AUTOSAR XML (schema 4-0-3)
standard types defined: Boolean, UInt16
package /AUTOSAR_Platform/DataConstrs
  range DC_Boolean: raw 0..1
  range DC_UInt16: raw 0..65535
package /PATAC/MSM/ComponentTypes
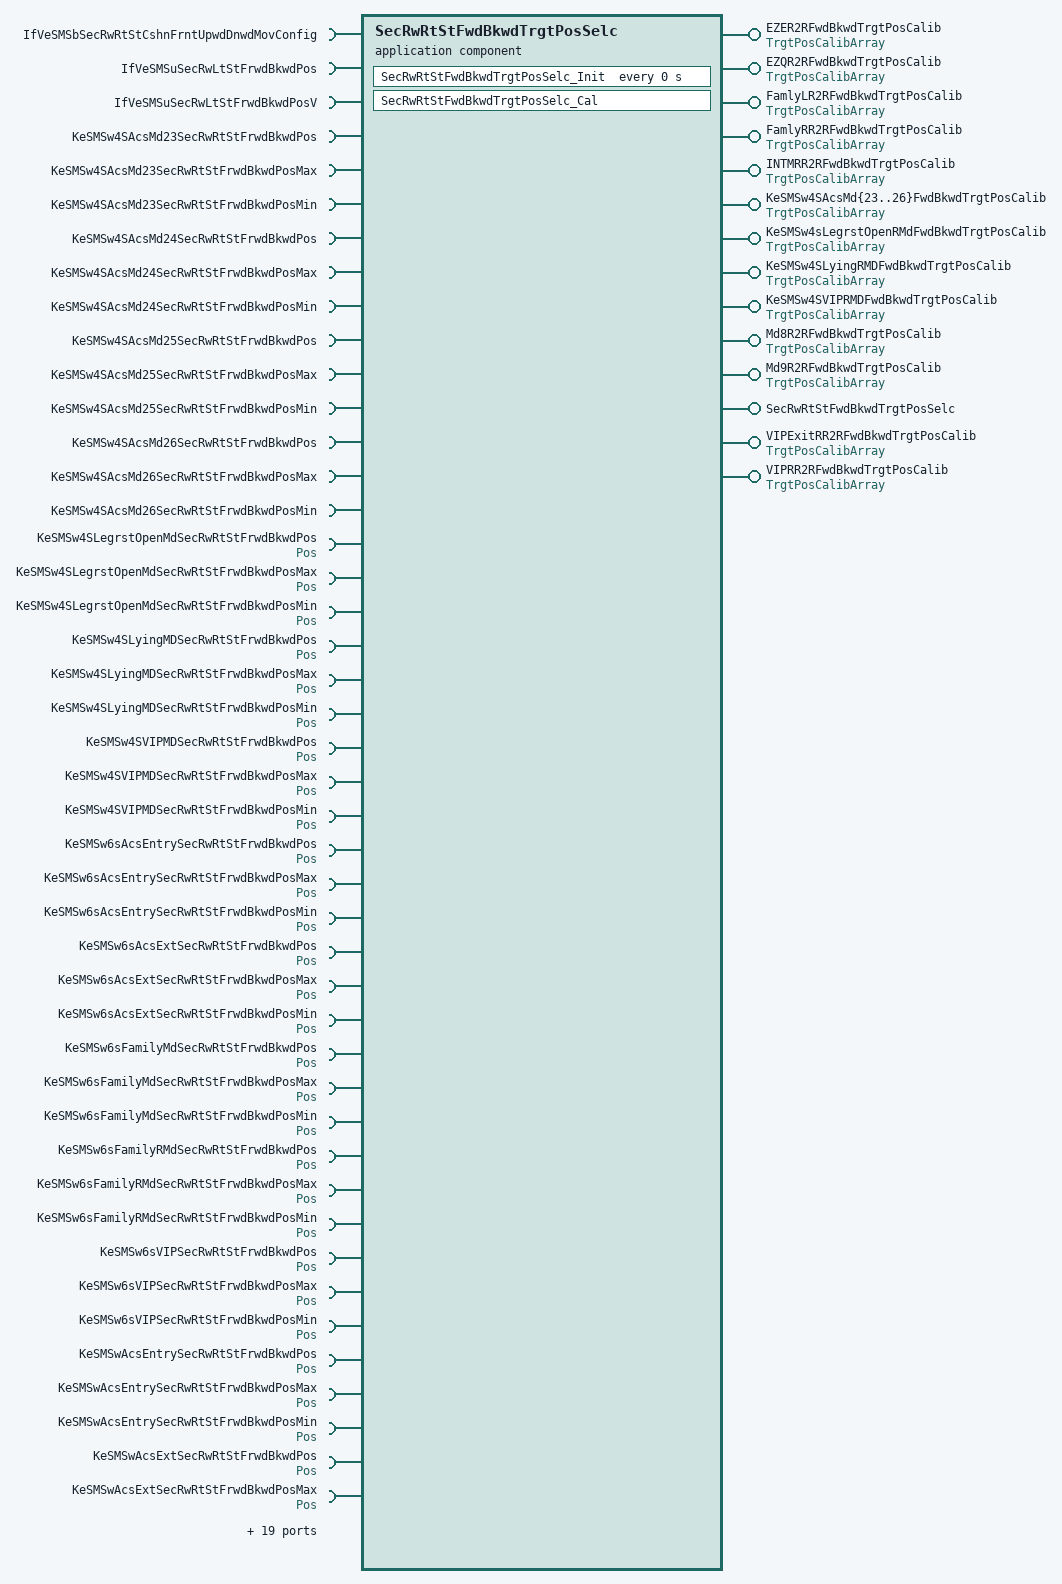
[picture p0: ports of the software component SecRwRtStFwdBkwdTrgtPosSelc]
  application sw component type SecRwRtStFwdBkwdTrgtPosSelc
    17 x provide port:
      EZER2RFwdBkwdTrgtPosCalib: nonqueued-sender-com-spec{data-element=TrgtPosArray, init-value=[4095, 4095, 4095]}, provided-interface=TrgtPosCalibArray
      EZQR2RFwdBkwdTrgtPosCalib: nonqueued-sender-com-spec{data-element=TrgtPosArray, init-value=[4095, 4095, 4095]}, provided-interface=TrgtPosCalibArray
      FamlyLR2RFwdBkwdTrgtPosCalib: nonqueued-sender-com-spec{data-element=TrgtPosArray, init-value=[4095, 4095, 4095]}, provided-interface=TrgtPosCalibArray
      FamlyRR2RFwdBkwdTrgtPosCalib: nonqueued-sender-com-spec{data-element=TrgtPosArray, init-value=[4095, 4095, 4095]}, provided-interface=TrgtPosCalibArray
      INTMRR2RFwdBkwdTrgtPosCalib: nonqueued-sender-com-spec{data-element=TrgtPosArray, init-value=[4095, 4095, 4095]}, provided-interface=TrgtPosCalibArray
      KeSMSw4SAcsMd{23..26}FwdBkwdTrgtPosCalib: nonqueued-sender-com-spec{data-element=TrgtPosArray, init-value=[4095, 4095, 4095]}, provided-interface=TrgtPosCalibArray
      KeSMSw4sLegrstOpenRMdFwdBkwdTrgtPosCalib: nonqueued-sender-com-spec{data-element=TrgtPosArray, init-value=[4095, 4095, 4095]}, provided-interface=TrgtPosCalibArray
      KeSMSw4SLyingRMDFwdBkwdTrgtPosCalib: nonqueued-sender-com-spec{data-element=TrgtPosArray, init-value=[4095, 4095, 4095]}, provided-interface=TrgtPosCalibArray
      KeSMSw4SVIPRMDFwdBkwdTrgtPosCalib: nonqueued-sender-com-spec{data-element=TrgtPosArray, init-value=[4095, 4095, 4095]}, provided-interface=TrgtPosCalibArray
      Md8R2RFwdBkwdTrgtPosCalib: nonqueued-sender-com-spec{data-element=TrgtPosArray, init-value=[4095, 4095, 4095]}, provided-interface=TrgtPosCalibArray
      Md9R2RFwdBkwdTrgtPosCalib: nonqueued-sender-com-spec{data-element=TrgtPosArray, init-value=[4095, 4095, 4095]}, provided-interface=TrgtPosCalibArray
      SecRwRtStFwdBkwdTrgtPosSelc: server-com-spec{operation=Cal, queue-length=1}, provided-interface=SecRwRtStFwdBkwdTrgtPosSelc
      VIPExitRR2RFwdBkwdTrgtPosCalib: nonqueued-sender-com-spec{data-element=TrgtPosArray, init-value=[4095, 4095, 4095]}, provided-interface=TrgtPosCalibArray
      VIPRR2RFwdBkwdTrgtPosCalib: nonqueued-sender-com-spec{data-element=TrgtPosArray, init-value=[4095, 4095, 4095]}, provided-interface=TrgtPosCalibArray
    63 x require port:
      IfVeSMSbSecRwRtStCshnFrntUpwdDnwdMovConfig: nonqueued-receiver-com-spec{data-element=IfVeSMSbSecRwRtStCshnFrntUpwdDnwdMovConfig/Val, filter=data-filter-type=ALWAYS, init-value=0}, required-interface=IfVeSMSbSecRwRtStCshnFrntUpwdDnwdMovConfig
      IfVeSMSuSecRwLtStFrwdBkwdPos: nonqueued-receiver-com-spec{data-element=IfVeSMSuSecRwLtStFrwdBkwdPos/Val, filter=data-filter-type=ALWAYS, init-value=0}, required-interface=IfVeSMSuSecRwLtStFrwdBkwdPos
      IfVeSMSuSecRwLtStFrwdBkwdPosV: nonqueued-receiver-com-spec{data-element=IfVeSMSuSecRwLtStFrwdBkwdPosV/Val, filter=data-filter-type=ALWAYS, init-value=0}, required-interface=IfVeSMSuSecRwLtStFrwdBkwdPosV
      KeSMSw4SAcsMd23SecRwRtStFrwdBkwdPos: parameter-require-com-spec{init-value=0, parameter=KeSMSw4SAcsMd23SecRwRtStFrwdBkwdPos/Val}, required-interface=KeSMSw4SAcsMd23SecRwRtStFrwdBkwdPos
      KeSMSw4SAcsMd23SecRwRtStFrwdBkwdPosMax: parameter-require-com-spec{init-value=0, parameter=KeSMSw4SAcsMd23SecRwRtStFrwdBkwdPosMax/Val}, required-interface=KeSMSw4SAcsMd23SecRwRtStFrwdBkwdPosMax
      KeSMSw4SAcsMd23SecRwRtStFrwdBkwdPosMin: parameter-require-com-spec{init-value=0, parameter=KeSMSw4SAcsMd23SecRwRtStFrwdBkwdPosMin/Val}, required-interface=KeSMSw4SAcsMd23SecRwRtStFrwdBkwdPosMin
      KeSMSw4SAcsMd24SecRwRtStFrwdBkwdPos: parameter-require-com-spec{init-value=0, parameter=KeSMSw4SAcsMd24SecRwRtStFrwdBkwdPos/Val}, required-interface=KeSMSw4SAcsMd24SecRwRtStFrwdBkwdPos
      KeSMSw4SAcsMd24SecRwRtStFrwdBkwdPosMax: parameter-require-com-spec{init-value=0, parameter=KeSMSw4SAcsMd24SecRwRtStFrwdBkwdPosMax/Val}, required-interface=KeSMSw4SAcsMd24SecRwRtStFrwdBkwdPosMax
      KeSMSw4SAcsMd24SecRwRtStFrwdBkwdPosMin: parameter-require-com-spec{init-value=0, parameter=KeSMSw4SAcsMd24SecRwRtStFrwdBkwdPosMin/Val}, required-interface=KeSMSw4SAcsMd24SecRwRtStFrwdBkwdPosMin
      KeSMSw4SAcsMd25SecRwRtStFrwdBkwdPos: parameter-require-com-spec{init-value=0, parameter=KeSMSw4SAcsMd25SecRwRtStFrwdBkwdPos/Val}, required-interface=KeSMSw4SAcsMd25SecRwRtStFrwdBkwdPos
      KeSMSw4SAcsMd25SecRwRtStFrwdBkwdPosMax: parameter-require-com-spec{init-value=0, parameter=KeSMSw4SAcsMd25SecRwRtStFrwdBkwdPosMax/Val}, required-interface=KeSMSw4SAcsMd25SecRwRtStFrwdBkwdPosMax
      KeSMSw4SAcsMd25SecRwRtStFrwdBkwdPosMin: parameter-require-com-spec{init-value=0, parameter=KeSMSw4SAcsMd25SecRwRtStFrwdBkwdPosMin/Val}, required-interface=KeSMSw4SAcsMd25SecRwRtStFrwdBkwdPosMin
      KeSMSw4SAcsMd26SecRwRtStFrwdBkwdPos: parameter-require-com-spec{init-value=0, parameter=KeSMSw4SAcsMd26SecRwRtStFrwdBkwdPos/Val}, required-interface=KeSMSw4SAcsMd26SecRwRtStFrwdBkwdPos
      KeSMSw4SAcsMd26SecRwRtStFrwdBkwdPosMax: parameter-require-com-spec{init-value=0, parameter=KeSMSw4SAcsMd26SecRwRtStFrwdBkwdPosMax/Val}, required-interface=KeSMSw4SAcsMd26SecRwRtStFrwdBkwdPosMax
      KeSMSw4SAcsMd26SecRwRtStFrwdBkwdPosMin: parameter-require-com-spec{init-value=0, parameter=KeSMSw4SAcsMd26SecRwRtStFrwdBkwdPosMin/Val}, required-interface=KeSMSw4SAcsMd26SecRwRtStFrwdBkwdPosMin
      KeSMSw4SLegrstOpenMdSecRwRtStFrwdBkwdPos: parameter-require-com-spec{init-value=2920, parameter=Pos/Val}, required-interface=Pos
      KeSMSw4SLegrstOpenMdSecRwRtStFrwdBkwdPosMax: parameter-require-com-spec{init-value=2920, parameter=Pos/Val}, required-interface=Pos
      KeSMSw4SLegrstOpenMdSecRwRtStFrwdBkwdPosMin: parameter-require-com-spec{init-value=2920, parameter=Pos/Val}, required-interface=Pos
      KeSMSw4SLyingMDSecRwRtStFrwdBkwdPos: parameter-require-com-spec{init-value=2920, parameter=Pos/Val}, required-interface=Pos
      KeSMSw4SLyingMDSecRwRtStFrwdBkwdPosMax: parameter-require-com-spec{init-value=2920, parameter=Pos/Val}, required-interface=Pos
      KeSMSw4SLyingMDSecRwRtStFrwdBkwdPosMin: parameter-require-com-spec{init-value=2920, parameter=Pos/Val}, required-interface=Pos
      KeSMSw4SVIPMDSecRwRtStFrwdBkwdPos: parameter-require-com-spec{init-value=2920, parameter=Pos/Val}, required-interface=Pos
      KeSMSw4SVIPMDSecRwRtStFrwdBkwdPosMax: parameter-require-com-spec{init-value=2920, parameter=Pos/Val}, required-interface=Pos
      KeSMSw4SVIPMDSecRwRtStFrwdBkwdPosMin: parameter-require-com-spec{init-value=2920, parameter=Pos/Val}, required-interface=Pos
      KeSMSw6sAcsEntrySecRwRtStFrwdBkwdPos: parameter-require-com-spec{init-value=727, parameter=Pos/Val}, required-interface=Pos
      KeSMSw6sAcsEntrySecRwRtStFrwdBkwdPosMax: parameter-require-com-spec{init-value=727, parameter=Pos/Val}, required-interface=Pos
      KeSMSw6sAcsEntrySecRwRtStFrwdBkwdPosMin: parameter-require-com-spec{init-value=727, parameter=Pos/Val}, required-interface=Pos
      KeSMSw6sAcsExtSecRwRtStFrwdBkwdPos: parameter-require-com-spec{init-value=727, parameter=Pos/Val}, required-interface=Pos
      KeSMSw6sAcsExtSecRwRtStFrwdBkwdPosMax: parameter-require-com-spec{init-value=727, parameter=Pos/Val}, required-interface=Pos
      KeSMSw6sAcsExtSecRwRtStFrwdBkwdPosMin: parameter-require-com-spec{init-value=727, parameter=Pos/Val}, required-interface=Pos
      KeSMSw6sFamilyMdSecRwRtStFrwdBkwdPos: parameter-require-com-spec{init-value=0, parameter=Pos/Val}, required-interface=Pos
      KeSMSw6sFamilyMdSecRwRtStFrwdBkwdPosMax: parameter-require-com-spec{init-value=0, parameter=Pos/Val}, required-interface=Pos
      KeSMSw6sFamilyMdSecRwRtStFrwdBkwdPosMin: parameter-require-com-spec{init-value=0, parameter=Pos/Val}, required-interface=Pos
      KeSMSw6sFamilyRMdSecRwRtStFrwdBkwdPos: parameter-require-com-spec{init-value=0, parameter=Pos/Val}, required-interface=Pos
      KeSMSw6sFamilyRMdSecRwRtStFrwdBkwdPosMax: parameter-require-com-spec{init-value=0, parameter=Pos/Val}, required-interface=Pos
      KeSMSw6sFamilyRMdSecRwRtStFrwdBkwdPosMin: parameter-require-com-spec{init-value=0, parameter=Pos/Val}, required-interface=Pos
      KeSMSw6sVIPSecRwRtStFrwdBkwdPos: parameter-require-com-spec{init-value=2920, parameter=Pos/Val}, required-interface=Pos
      KeSMSw6sVIPSecRwRtStFrwdBkwdPosMax: parameter-require-com-spec{init-value=2920, parameter=Pos/Val}, required-interface=Pos
      KeSMSw6sVIPSecRwRtStFrwdBkwdPosMin: parameter-require-com-spec{init-value=2920, parameter=Pos/Val}, required-interface=Pos
      KeSMSwAcsEntrySecRwRtStFrwdBkwdPos: parameter-require-com-spec{init-value=727, parameter=Pos/Val}, required-interface=Pos
      KeSMSwAcsEntrySecRwRtStFrwdBkwdPosMax: parameter-require-com-spec{init-value=727, parameter=Pos/Val}, required-interface=Pos
      KeSMSwAcsEntrySecRwRtStFrwdBkwdPosMin: parameter-require-com-spec{init-value=727, parameter=Pos/Val}, required-interface=Pos
      KeSMSwAcsExtSecRwRtStFrwdBkwdPos: parameter-require-com-spec{init-value=727, parameter=Pos/Val}, required-interface=Pos
      KeSMSwAcsExtSecRwRtStFrwdBkwdPosMax: parameter-require-com-spec{init-value=727, parameter=Pos/Val}, required-interface=Pos
      KeSMSwAcsExtSecRwRtStFrwdBkwdPosMin: parameter-require-com-spec{init-value=727, parameter=Pos/Val}, required-interface=Pos
      KeSMSwAcsMd8SecRwRtStFrwdBkwdPos: parameter-require-com-spec{init-value=0, parameter=Pos/Val}, required-interface=Pos
      KeSMSwAcsMd8SecRwRtStFrwdBkwdPosMax: parameter-require-com-spec{init-value=0, parameter=Pos/Val}, required-interface=Pos
      KeSMSwAcsMd8SecRwRtStFrwdBkwdPosMin: parameter-require-com-spec{init-value=0, parameter=Pos/Val}, required-interface=Pos
      KeSMSwAcsMd9SecRwRtStFrwdBkwdPos: parameter-require-com-spec{init-value=0, parameter=Pos/Val}, required-interface=Pos
      KeSMSwAcsMd9SecRwRtStFrwdBkwdPosMax: parameter-require-com-spec{init-value=0, parameter=Pos/Val}, required-interface=Pos
      KeSMSwAcsMd9SecRwRtStFrwdBkwdPosMin: parameter-require-com-spec{init-value=0, parameter=Pos/Val}, required-interface=Pos
      KeSMSwFamilyMdSecRwRtStFrwdBkwdPos: parameter-require-com-spec{init-value=0, parameter=Pos/Val}, required-interface=Pos
      KeSMSwFamilyMdSecRwRtStFrwdBkwdPosMax: parameter-require-com-spec{init-value=0, parameter=Pos/Val}, required-interface=Pos
      KeSMSwFamilyMdSecRwRtStFrwdBkwdPosMin: parameter-require-com-spec{init-value=0, parameter=Pos/Val}, required-interface=Pos
      KeSMSwFamilyRMdSecRwRtStFrwdBkwdPos: parameter-require-com-spec{init-value=0, parameter=Pos/Val}, required-interface=Pos
      KeSMSwFamilyRMdSecRwRtStFrwdBkwdPosMax: parameter-require-com-spec{init-value=0, parameter=Pos/Val}, required-interface=Pos
      KeSMSwFamilyRMdSecRwRtStFrwdBkwdPosMin: parameter-require-com-spec{init-value=0, parameter=Pos/Val}, required-interface=Pos
      KeSMSwVIPSecRwRtStFrwdBkwdPos: parameter-require-com-spec{init-value=2920, parameter=Pos/Val}, required-interface=Pos
      KeSMSwVIPSecRwRtStFrwdBkwdPosMax: parameter-require-com-spec{init-value=2920, parameter=Pos/Val}, required-interface=Pos
      KeSMSwVIPSecRwRtStFrwdBkwdPosMin: parameter-require-com-spec{init-value=2920, parameter=Pos/Val}, required-interface=Pos
      StNumFlg: required-interface=StNumFlg
        required-com-specs:
          data-element=Is4s, filter=data-filter-type=ALWAYS, init-value=0
          data-element=Is6s, filter=data-filter-type=ALWAYS, init-value=0
          data-element=Is6s7s, filter=data-filter-type=ALWAYS, init-value=0
          data-element=Is7s, filter=data-filter-type=ALWAYS, init-value=0
      VIPR557TrgtPos: required-com-specs=[VIPR557TrgtPos/Get, VIPR557TrgtPos/Set], required-interface=VIPR557TrgtPos
      VIPRExit557TrgtPos: required-com-specs=[VIPRExit557TrgtPos/Get, VIPRExit557TrgtPos/Set], required-interface=VIPRExit557TrgtPos
    behavior SecRwRtStFwdBkwdTrgtPosSelc_InternalBehavior
      operation invoked event OIT_SecRwRtStFwdBkwdTrgtPosSelc_Cal_SecRwRtStFwdBkwdTrgtPosSelc_Cal: start-on-event=SecRwRtStFwdBkwdTrgtPosSelc_Cal, operation=SecRwRtStFwdBkwdTrgtPosSelc.Cal
      timing event SecRwRtStFwdBkwdTrgtPosSelc_InitEvent: start-on-event=SecRwRtStFwdBkwdTrgtPosSelc_Init, period=0
      runnable SecRwRtStFwdBkwdTrgtPosSelc_Cal
        data-receive-point-by-arguments:
          7 x access:
            REC_IfVeSMSbSecRwRtStCshnFrntUpwdDnwdMovConfig_Val: accessed-variable=IfVeSMSbSecRwRtStCshnFrntUpwdDnwdMovConfig.Val
            REC_IfVeSMSuSecRwLtStFrwdBkwdPos_Val: accessed-variable=IfVeSMSuSecRwLtStFrwdBkwdPos.Val
            REC_IfVeSMSuSecRwLtStFrwdBkwdPosV_Val: accessed-variable=IfVeSMSuSecRwLtStFrwdBkwdPosV.Val
            REC_StNumFlg_Is4s: accessed-variable=StNumFlg.Is4s
            REC_StNumFlg_Is6s: accessed-variable=StNumFlg.Is6s
            REC_StNumFlg_Is6s7s: accessed-variable=StNumFlg.Is6s7s
            REC_StNumFlg_Is7s: accessed-variable=StNumFlg.Is7s
        data-send-points:
          16 x access:
            SEND_EZER2RFwdBkwdTrgtPosCalib_TrgtPosArray: accessed-variable=EZER2RFwdBkwdTrgtPosCalib.TrgtPosArray
            SEND_EZQR2RFwdBkwdTrgtPosCalib_TrgtPosArray: accessed-variable=EZQR2RFwdBkwdTrgtPosCalib.TrgtPosArray
            SEND_FamlyLR2RFwdBkwdTrgtPosCalib_TrgtPosArray: accessed-variable=FamlyLR2RFwdBkwdTrgtPosCalib.TrgtPosArray
            SEND_FamlyRR2RFwdBkwdTrgtPosCalib_TrgtPosArray: accessed-variable=FamlyRR2RFwdBkwdTrgtPosCalib.TrgtPosArray
            SEND_INTMRR2RFwdBkwdTrgtPosCalib_TrgtPosArray: accessed-variable=INTMRR2RFwdBkwdTrgtPosCalib.TrgtPosArray
            SEND_KeSMSw4SAcsMd{23..26}FwdBkwdTrgtPosCalib_TrgtPosArray: accessed-variable=KeSMSw4SAcsMd{23..26}FwdBkwdTrgtPosCalib.TrgtPosArray
            SEND_KeSMSw4sLegrstOpenRMdFwdBkwdTrgtPosCalib_TrgtPosArray: accessed-variable=KeSMSw4sLegrstOpenRMdFwdBkwdTrgtPosCalib.TrgtPosArray
            SEND_KeSMSw4SLyingRMDFwdBkwdTrgtPosCalib_TrgtPosArray: accessed-variable=KeSMSw4SLyingRMDFwdBkwdTrgtPosCalib.TrgtPosArray
            SEND_KeSMSw4SVIPRMDFwdBkwdTrgtPosCalib_TrgtPosArray: accessed-variable=KeSMSw4SVIPRMDFwdBkwdTrgtPosCalib.TrgtPosArray
            SEND_Md8R2RFwdBkwdTrgtPosCalib_TrgtPosArray: accessed-variable=Md8R2RFwdBkwdTrgtPosCalib.TrgtPosArray
            SEND_Md9R2RFwdBkwdTrgtPosCalib_TrgtPosArray: accessed-variable=Md9R2RFwdBkwdTrgtPosCalib.TrgtPosArray
            SEND_VIPExitRR2RFwdBkwdTrgtPosCalib_TrgtPosArray: accessed-variable=VIPExitRR2RFwdBkwdTrgtPosCalib.TrgtPosArray
            SEND_VIPRR2RFwdBkwdTrgtPosCalib_TrgtPosArray: accessed-variable=VIPRR2RFwdBkwdTrgtPosCalib.TrgtPosArray
        57 x parameter access:
          PA_KeSMSw4SAcsMd23SecRwRtStFrwdBkwdPos_Val: accessed-parameter=KeSMSw4SAcsMd23SecRwRtStFrwdBkwdPos.Val
          PA_KeSMSw4SAcsMd23SecRwRtStFrwdBkwdPosMax_Val: accessed-parameter=KeSMSw4SAcsMd23SecRwRtStFrwdBkwdPosMax.Val
          PA_KeSMSw4SAcsMd23SecRwRtStFrwdBkwdPosMin_Val: accessed-parameter=KeSMSw4SAcsMd23SecRwRtStFrwdBkwdPosMin.Val
          PA_KeSMSw4SAcsMd24SecRwRtStFrwdBkwdPos_Val: accessed-parameter=KeSMSw4SAcsMd24SecRwRtStFrwdBkwdPos.Val
          PA_KeSMSw4SAcsMd24SecRwRtStFrwdBkwdPosMax_Val: accessed-parameter=KeSMSw4SAcsMd24SecRwRtStFrwdBkwdPosMax.Val
          PA_KeSMSw4SAcsMd24SecRwRtStFrwdBkwdPosMin_Val: accessed-parameter=KeSMSw4SAcsMd24SecRwRtStFrwdBkwdPosMin.Val
          PA_KeSMSw4SAcsMd25SecRwRtStFrwdBkwdPos_Val: accessed-parameter=KeSMSw4SAcsMd25SecRwRtStFrwdBkwdPos.Val
          PA_KeSMSw4SAcsMd25SecRwRtStFrwdBkwdPosMax_Val: accessed-parameter=KeSMSw4SAcsMd25SecRwRtStFrwdBkwdPosMax.Val
          PA_KeSMSw4SAcsMd25SecRwRtStFrwdBkwdPosMin_Val: accessed-parameter=KeSMSw4SAcsMd25SecRwRtStFrwdBkwdPosMin.Val
          PA_KeSMSw4SAcsMd26SecRwRtStFrwdBkwdPos_Val: accessed-parameter=KeSMSw4SAcsMd26SecRwRtStFrwdBkwdPos.Val
          PA_KeSMSw4SAcsMd26SecRwRtStFrwdBkwdPosMax_Val: accessed-parameter=KeSMSw4SAcsMd26SecRwRtStFrwdBkwdPosMax.Val
          PA_KeSMSw4SAcsMd26SecRwRtStFrwdBkwdPosMin_Val: accessed-parameter=KeSMSw4SAcsMd26SecRwRtStFrwdBkwdPosMin.Val
          PA_KeSMSw4SLegrstOpenMdSecRwRtStFrwdBkwdPos_Val: accessed-parameter=KeSMSw4SLegrstOpenMdSecRwRtStFrwdBkwdPos.Val
          PA_KeSMSw4SLegrstOpenMdSecRwRtStFrwdBkwdPosMax_Val: accessed-parameter=KeSMSw4SLegrstOpenMdSecRwRtStFrwdBkwdPosMax.Val
          PA_KeSMSw4SLegrstOpenMdSecRwRtStFrwdBkwdPosMin_Val: accessed-parameter=KeSMSw4SLegrstOpenMdSecRwRtStFrwdBkwdPosMin.Val
          PA_KeSMSw4SLyingMDSecRwRtStFrwdBkwdPos_Val: accessed-parameter=KeSMSw4SLyingMDSecRwRtStFrwdBkwdPos.Val
          PA_KeSMSw4SLyingMDSecRwRtStFrwdBkwdPosMax_Val: accessed-parameter=KeSMSw4SLyingMDSecRwRtStFrwdBkwdPosMax.Val
          PA_KeSMSw4SLyingMDSecRwRtStFrwdBkwdPosMin_Val: accessed-parameter=KeSMSw4SLyingMDSecRwRtStFrwdBkwdPosMin.Val
          PA_KeSMSw4SVIPMDSecRwRtStFrwdBkwdPos_Val: accessed-parameter=KeSMSw4SVIPMDSecRwRtStFrwdBkwdPos.Val
          PA_KeSMSw4SVIPMDSecRwRtStFrwdBkwdPosMax_Val: accessed-parameter=KeSMSw4SVIPMDSecRwRtStFrwdBkwdPosMax.Val
          PA_KeSMSw4SVIPMDSecRwRtStFrwdBkwdPosMin_Val: accessed-parameter=KeSMSw4SVIPMDSecRwRtStFrwdBkwdPosMin.Val
          PA_KeSMSw6sAcsEntrySecRwRtStFrwdBkwdPos_Val: accessed-parameter=KeSMSw6sAcsEntrySecRwRtStFrwdBkwdPos.Val
          PA_KeSMSw6sAcsEntrySecRwRtStFrwdBkwdPosMax_Val: accessed-parameter=KeSMSw6sAcsEntrySecRwRtStFrwdBkwdPosMax.Val
          PA_KeSMSw6sAcsEntrySecRwRtStFrwdBkwdPosMin_Val: accessed-parameter=KeSMSw6sAcsEntrySecRwRtStFrwdBkwdPosMin.Val
          PA_KeSMSw6sAcsExtSecRwRtStFrwdBkwdPos_Val: accessed-parameter=KeSMSw6sAcsExtSecRwRtStFrwdBkwdPos.Val
          PA_KeSMSw6sAcsExtSecRwRtStFrwdBkwdPosMax_Val: accessed-parameter=KeSMSw6sAcsExtSecRwRtStFrwdBkwdPosMax.Val
          PA_KeSMSw6sAcsExtSecRwRtStFrwdBkwdPosMin_Val: accessed-parameter=KeSMSw6sAcsExtSecRwRtStFrwdBkwdPosMin.Val
          PA_KeSMSw6sFamilyMdSecRwRtStFrwdBkwdPos_Val: accessed-parameter=KeSMSw6sFamilyMdSecRwRtStFrwdBkwdPos.Val
          PA_KeSMSw6sFamilyMdSecRwRtStFrwdBkwdPosMax_Val: accessed-parameter=KeSMSw6sFamilyMdSecRwRtStFrwdBkwdPosMax.Val
          PA_KeSMSw6sFamilyMdSecRwRtStFrwdBkwdPosMin_Val: accessed-parameter=KeSMSw6sFamilyMdSecRwRtStFrwdBkwdPosMin.Val
          PA_KeSMSw6sFamilyRMdSecRwRtStFrwdBkwdPos_Val: accessed-parameter=KeSMSw6sFamilyRMdSecRwRtStFrwdBkwdPos.Val
          PA_KeSMSw6sFamilyRMdSecRwRtStFrwdBkwdPosMax_Val: accessed-parameter=KeSMSw6sFamilyRMdSecRwRtStFrwdBkwdPosMax.Val
          PA_KeSMSw6sFamilyRMdSecRwRtStFrwdBkwdPosMin_Val: accessed-parameter=KeSMSw6sFamilyRMdSecRwRtStFrwdBkwdPosMin.Val
          PA_KeSMSw6sVIPSecRwRtStFrwdBkwdPos_Val: accessed-parameter=KeSMSw6sVIPSecRwRtStFrwdBkwdPos.Val
          PA_KeSMSw6sVIPSecRwRtStFrwdBkwdPosMax_Val: accessed-parameter=KeSMSw6sVIPSecRwRtStFrwdBkwdPosMax.Val
          PA_KeSMSw6sVIPSecRwRtStFrwdBkwdPosMin_Val: accessed-parameter=KeSMSw6sVIPSecRwRtStFrwdBkwdPosMin.Val
          PA_KeSMSwAcsEntrySecRwRtStFrwdBkwdPos_Val: accessed-parameter=KeSMSwAcsEntrySecRwRtStFrwdBkwdPos.Val
          PA_KeSMSwAcsEntrySecRwRtStFrwdBkwdPosMax_Val: accessed-parameter=KeSMSwAcsEntrySecRwRtStFrwdBkwdPosMax.Val
          PA_KeSMSwAcsEntrySecRwRtStFrwdBkwdPosMin_Val: accessed-parameter=KeSMSwAcsEntrySecRwRtStFrwdBkwdPosMin.Val
          PA_KeSMSwAcsExtSecRwRtStFrwdBkwdPos_Val: accessed-parameter=KeSMSwAcsExtSecRwRtStFrwdBkwdPos.Val
          PA_KeSMSwAcsExtSecRwRtStFrwdBkwdPosMax_Val: accessed-parameter=KeSMSwAcsExtSecRwRtStFrwdBkwdPosMax.Val
          PA_KeSMSwAcsExtSecRwRtStFrwdBkwdPosMin_Val: accessed-parameter=KeSMSwAcsExtSecRwRtStFrwdBkwdPosMin.Val
          PA_KeSMSwAcsMd8SecRwRtStFrwdBkwdPos_Val: accessed-parameter=KeSMSwAcsMd8SecRwRtStFrwdBkwdPos.Val
          PA_KeSMSwAcsMd8SecRwRtStFrwdBkwdPosMax_Val: accessed-parameter=KeSMSwAcsMd8SecRwRtStFrwdBkwdPosMax.Val
          PA_KeSMSwAcsMd8SecRwRtStFrwdBkwdPosMin_Val: accessed-parameter=KeSMSwAcsMd8SecRwRtStFrwdBkwdPosMin.Val
          PA_KeSMSwAcsMd9SecRwRtStFrwdBkwdPos_Val: accessed-parameter=KeSMSwAcsMd9SecRwRtStFrwdBkwdPos.Val
          PA_KeSMSwAcsMd9SecRwRtStFrwdBkwdPosMax_Val: accessed-parameter=KeSMSwAcsMd9SecRwRtStFrwdBkwdPosMax.Val
          PA_KeSMSwAcsMd9SecRwRtStFrwdBkwdPosMin_Val: accessed-parameter=KeSMSwAcsMd9SecRwRtStFrwdBkwdPosMin.Val
          PA_KeSMSwFamilyMdSecRwRtStFrwdBkwdPos_Val: accessed-parameter=KeSMSwFamilyMdSecRwRtStFrwdBkwdPos.Val
          PA_KeSMSwFamilyMdSecRwRtStFrwdBkwdPosMax_Val: accessed-parameter=KeSMSwFamilyMdSecRwRtStFrwdBkwdPosMax.Val
          PA_KeSMSwFamilyMdSecRwRtStFrwdBkwdPosMin_Val: accessed-parameter=KeSMSwFamilyMdSecRwRtStFrwdBkwdPosMin.Val
          PA_KeSMSwFamilyRMdSecRwRtStFrwdBkwdPos_Val: accessed-parameter=KeSMSwFamilyRMdSecRwRtStFrwdBkwdPos.Val
          PA_KeSMSwFamilyRMdSecRwRtStFrwdBkwdPosMax_Val: accessed-parameter=KeSMSwFamilyRMdSecRwRtStFrwdBkwdPosMax.Val
          PA_KeSMSwFamilyRMdSecRwRtStFrwdBkwdPosMin_Val: accessed-parameter=KeSMSwFamilyRMdSecRwRtStFrwdBkwdPosMin.Val
          PA_KeSMSwVIPSecRwRtStFrwdBkwdPos_Val: accessed-parameter=KeSMSwVIPSecRwRtStFrwdBkwdPos.Val
          PA_KeSMSwVIPSecRwRtStFrwdBkwdPosMax_Val: accessed-parameter=KeSMSwVIPSecRwRtStFrwdBkwdPosMax.Val
          PA_KeSMSwVIPSecRwRtStFrwdBkwdPosMin_Val: accessed-parameter=KeSMSwVIPSecRwRtStFrwdBkwdPosMin.Val
        sync call SC_VIPR557TrgtPos_Get: operation=VIPR557TrgtPos.Get, timeout=0
        sync call SC_VIPRExit557TrgtPos_Get: operation=VIPRExit557TrgtPos.Get, timeout=0
      runnable SecRwRtStFwdBkwdTrgtPosSelc_Init
        57 x parameter access:
          PA_KeSMSw4SAcsMd23SecRwRtStFrwdBkwdPos_Val: accessed-parameter=KeSMSw4SAcsMd23SecRwRtStFrwdBkwdPos.Val
          PA_KeSMSw4SAcsMd23SecRwRtStFrwdBkwdPosMax_Val: accessed-parameter=KeSMSw4SAcsMd23SecRwRtStFrwdBkwdPosMax.Val
          PA_KeSMSw4SAcsMd23SecRwRtStFrwdBkwdPosMin_Val: accessed-parameter=KeSMSw4SAcsMd23SecRwRtStFrwdBkwdPosMin.Val
          PA_KeSMSw4SAcsMd24SecRwRtStFrwdBkwdPos_Val: accessed-parameter=KeSMSw4SAcsMd24SecRwRtStFrwdBkwdPos.Val
          PA_KeSMSw4SAcsMd24SecRwRtStFrwdBkwdPosMax_Val: accessed-parameter=KeSMSw4SAcsMd24SecRwRtStFrwdBkwdPosMax.Val
          PA_KeSMSw4SAcsMd24SecRwRtStFrwdBkwdPosMin_Val: accessed-parameter=KeSMSw4SAcsMd24SecRwRtStFrwdBkwdPosMin.Val
          PA_KeSMSw4SAcsMd25SecRwRtStFrwdBkwdPos_Val: accessed-parameter=KeSMSw4SAcsMd25SecRwRtStFrwdBkwdPos.Val
          PA_KeSMSw4SAcsMd25SecRwRtStFrwdBkwdPosMax_Val: accessed-parameter=KeSMSw4SAcsMd25SecRwRtStFrwdBkwdPosMax.Val
          PA_KeSMSw4SAcsMd25SecRwRtStFrwdBkwdPosMin_Val: accessed-parameter=KeSMSw4SAcsMd25SecRwRtStFrwdBkwdPosMin.Val
          PA_KeSMSw4SAcsMd26SecRwRtStFrwdBkwdPos_Val: accessed-parameter=KeSMSw4SAcsMd26SecRwRtStFrwdBkwdPos.Val
          PA_KeSMSw4SAcsMd26SecRwRtStFrwdBkwdPosMax_Val: accessed-parameter=KeSMSw4SAcsMd26SecRwRtStFrwdBkwdPosMax.Val
          PA_KeSMSw4SAcsMd26SecRwRtStFrwdBkwdPosMin_Val: accessed-parameter=KeSMSw4SAcsMd26SecRwRtStFrwdBkwdPosMin.Val
          PA_KeSMSw4SLegrstOpenMdSecRwRtStFrwdBkwdPos_Val: accessed-parameter=KeSMSw4SLegrstOpenMdSecRwRtStFrwdBkwdPos.Val
          PA_KeSMSw4SLegrstOpenMdSecRwRtStFrwdBkwdPosMax_Val: accessed-parameter=KeSMSw4SLegrstOpenMdSecRwRtStFrwdBkwdPosMax.Val
          PA_KeSMSw4SLegrstOpenMdSecRwRtStFrwdBkwdPosMin_Val: accessed-parameter=KeSMSw4SLegrstOpenMdSecRwRtStFrwdBkwdPosMin.Val
          PA_KeSMSw4SLyingMDSecRwRtStFrwdBkwdPos_Val: accessed-parameter=KeSMSw4SLyingMDSecRwRtStFrwdBkwdPos.Val
          PA_KeSMSw4SLyingMDSecRwRtStFrwdBkwdPosMax_Val: accessed-parameter=KeSMSw4SLyingMDSecRwRtStFrwdBkwdPosMax.Val
          PA_KeSMSw4SLyingMDSecRwRtStFrwdBkwdPosMin_Val: accessed-parameter=KeSMSw4SLyingMDSecRwRtStFrwdBkwdPosMin.Val
          PA_KeSMSw4SVIPMDSecRwRtStFrwdBkwdPos_Val: accessed-parameter=KeSMSw4SVIPMDSecRwRtStFrwdBkwdPos.Val
          PA_KeSMSw4SVIPMDSecRwRtStFrwdBkwdPosMax_Val: accessed-parameter=KeSMSw4SVIPMDSecRwRtStFrwdBkwdPosMax.Val
          PA_KeSMSw4SVIPMDSecRwRtStFrwdBkwdPosMin_Val: accessed-parameter=KeSMSw4SVIPMDSecRwRtStFrwdBkwdPosMin.Val
          PA_KeSMSw6sAcsEntrySecRwRtStFrwdBkwdPos_Val: accessed-parameter=KeSMSw6sAcsEntrySecRwRtStFrwdBkwdPos.Val
          PA_KeSMSw6sAcsEntrySecRwRtStFrwdBkwdPosMax_Val: accessed-parameter=KeSMSw6sAcsEntrySecRwRtStFrwdBkwdPosMax.Val
          PA_KeSMSw6sAcsEntrySecRwRtStFrwdBkwdPosMin_Val: accessed-parameter=KeSMSw6sAcsEntrySecRwRtStFrwdBkwdPosMin.Val
          PA_KeSMSw6sAcsExtSecRwRtStFrwdBkwdPos_Val: accessed-parameter=KeSMSw6sAcsExtSecRwRtStFrwdBkwdPos.Val
          PA_KeSMSw6sAcsExtSecRwRtStFrwdBkwdPosMax_Val: accessed-parameter=KeSMSw6sAcsExtSecRwRtStFrwdBkwdPosMax.Val
          PA_KeSMSw6sAcsExtSecRwRtStFrwdBkwdPosMin_Val: accessed-parameter=KeSMSw6sAcsExtSecRwRtStFrwdBkwdPosMin.Val
          PA_KeSMSw6sFamilyMdSecRwRtStFrwdBkwdPos_Val: accessed-parameter=KeSMSw6sFamilyMdSecRwRtStFrwdBkwdPos.Val
          PA_KeSMSw6sFamilyMdSecRwRtStFrwdBkwdPosMax_Val: accessed-parameter=KeSMSw6sFamilyMdSecRwRtStFrwdBkwdPosMax.Val
          PA_KeSMSw6sFamilyMdSecRwRtStFrwdBkwdPosMin_Val: accessed-parameter=KeSMSw6sFamilyMdSecRwRtStFrwdBkwdPosMin.Val
          PA_KeSMSw6sFamilyRMdSecRwRtStFrwdBkwdPos_Val: accessed-parameter=KeSMSw6sFamilyRMdSecRwRtStFrwdBkwdPos.Val
          PA_KeSMSw6sFamilyRMdSecRwRtStFrwdBkwdPosMax_Val: accessed-parameter=KeSMSw6sFamilyRMdSecRwRtStFrwdBkwdPosMax.Val
          PA_KeSMSw6sFamilyRMdSecRwRtStFrwdBkwdPosMin_Val: accessed-parameter=KeSMSw6sFamilyRMdSecRwRtStFrwdBkwdPosMin.Val
          PA_KeSMSw6sVIPSecRwRtStFrwdBkwdPos_Val: accessed-parameter=KeSMSw6sVIPSecRwRtStFrwdBkwdPos.Val
          PA_KeSMSw6sVIPSecRwRtStFrwdBkwdPosMax_Val: accessed-parameter=KeSMSw6sVIPSecRwRtStFrwdBkwdPosMax.Val
          PA_KeSMSw6sVIPSecRwRtStFrwdBkwdPosMin_Val: accessed-parameter=KeSMSw6sVIPSecRwRtStFrwdBkwdPosMin.Val
          PA_KeSMSwAcsEntrySecRwRtStFrwdBkwdPos_Val: accessed-parameter=KeSMSwAcsEntrySecRwRtStFrwdBkwdPos.Val
          PA_KeSMSwAcsEntrySecRwRtStFrwdBkwdPosMax_Val: accessed-parameter=KeSMSwAcsEntrySecRwRtStFrwdBkwdPosMax.Val
          PA_KeSMSwAcsEntrySecRwRtStFrwdBkwdPosMin_Val: accessed-parameter=KeSMSwAcsEntrySecRwRtStFrwdBkwdPosMin.Val
          PA_KeSMSwAcsExtSecRwRtStFrwdBkwdPos_Val: accessed-parameter=KeSMSwAcsExtSecRwRtStFrwdBkwdPos.Val
          PA_KeSMSwAcsExtSecRwRtStFrwdBkwdPosMax_Val: accessed-parameter=KeSMSwAcsExtSecRwRtStFrwdBkwdPosMax.Val
          PA_KeSMSwAcsExtSecRwRtStFrwdBkwdPosMin_Val: accessed-parameter=KeSMSwAcsExtSecRwRtStFrwdBkwdPosMin.Val
          PA_KeSMSwAcsMd8SecRwRtStFrwdBkwdPos_Val: accessed-parameter=KeSMSwAcsMd8SecRwRtStFrwdBkwdPos.Val
          PA_KeSMSwAcsMd8SecRwRtStFrwdBkwdPosMax_Val: accessed-parameter=KeSMSwAcsMd8SecRwRtStFrwdBkwdPosMax.Val
          PA_KeSMSwAcsMd8SecRwRtStFrwdBkwdPosMin_Val: accessed-parameter=KeSMSwAcsMd8SecRwRtStFrwdBkwdPosMin.Val
          PA_KeSMSwAcsMd9SecRwRtStFrwdBkwdPos_Val: accessed-parameter=KeSMSwAcsMd9SecRwRtStFrwdBkwdPos.Val
          PA_KeSMSwAcsMd9SecRwRtStFrwdBkwdPosMax_Val: accessed-parameter=KeSMSwAcsMd9SecRwRtStFrwdBkwdPosMax.Val
          PA_KeSMSwAcsMd9SecRwRtStFrwdBkwdPosMin_Val: accessed-parameter=KeSMSwAcsMd9SecRwRtStFrwdBkwdPosMin.Val
          PA_KeSMSwFamilyMdSecRwRtStFrwdBkwdPos_Val: accessed-parameter=KeSMSwFamilyMdSecRwRtStFrwdBkwdPos.Val
          PA_KeSMSwFamilyMdSecRwRtStFrwdBkwdPosMax_Val: accessed-parameter=KeSMSwFamilyMdSecRwRtStFrwdBkwdPosMax.Val
          PA_KeSMSwFamilyMdSecRwRtStFrwdBkwdPosMin_Val: accessed-parameter=KeSMSwFamilyMdSecRwRtStFrwdBkwdPosMin.Val
          PA_KeSMSwFamilyRMdSecRwRtStFrwdBkwdPos_Val: accessed-parameter=KeSMSwFamilyRMdSecRwRtStFrwdBkwdPos.Val
          PA_KeSMSwFamilyRMdSecRwRtStFrwdBkwdPosMax_Val: accessed-parameter=KeSMSwFamilyRMdSecRwRtStFrwdBkwdPosMax.Val
          PA_KeSMSwFamilyRMdSecRwRtStFrwdBkwdPosMin_Val: accessed-parameter=KeSMSwFamilyRMdSecRwRtStFrwdBkwdPosMin.Val
          PA_KeSMSwVIPSecRwRtStFrwdBkwdPos_Val: accessed-parameter=KeSMSwVIPSecRwRtStFrwdBkwdPos.Val
          PA_KeSMSwVIPSecRwRtStFrwdBkwdPosMax_Val: accessed-parameter=KeSMSwVIPSecRwRtStFrwdBkwdPosMax.Val
          PA_KeSMSwVIPSecRwRtStFrwdBkwdPosMin_Val: accessed-parameter=KeSMSwVIPSecRwRtStFrwdBkwdPosMin.Val
  swc implementation SecRwRtStFwdBkwdTrgtPosSelc_Implementation: behavior=SecRwRtStFwdBkwdTrgtPosSelc_InternalBehavior
    code-descriptors:
      code Default: artifact-descriptors=autosar-engineering-object={short-label=Default, category=SWSRC}
package /PATAC/MSM/ModeAdjust/CalPortInterface
  13 x parameter interface:
    KeSMSw4SAcsMd23SecRwRtStFrwdBkwdPos
      parameter data prototype Val: sw-calibration-access=READ-WRITE, type=UInt16
    KeSMSw4SAcsMd23SecRwRtStFrwdBkwdPosMax
      parameter data prototype Val: sw-calibration-access=READ-WRITE, type=UInt16
    KeSMSw4SAcsMd23SecRwRtStFrwdBkwdPosMin
      parameter data prototype Val: sw-calibration-access=READ-WRITE, type=UInt16
    KeSMSw4SAcsMd24SecRwRtStFrwdBkwdPos
      parameter data prototype Val: sw-calibration-access=READ-WRITE, type=UInt16
    KeSMSw4SAcsMd24SecRwRtStFrwdBkwdPosMax
      parameter data prototype Val: sw-calibration-access=READ-WRITE, type=UInt16
    KeSMSw4SAcsMd24SecRwRtStFrwdBkwdPosMin
      parameter data prototype Val: sw-calibration-access=READ-WRITE, type=UInt16
    KeSMSw4SAcsMd25SecRwRtStFrwdBkwdPos
      parameter data prototype Val: sw-calibration-access=READ-WRITE, type=UInt16
    KeSMSw4SAcsMd25SecRwRtStFrwdBkwdPosMax
      parameter data prototype Val: sw-calibration-access=READ-WRITE, type=UInt16
    KeSMSw4SAcsMd25SecRwRtStFrwdBkwdPosMin
      parameter data prototype Val: sw-calibration-access=READ-WRITE, type=UInt16
    KeSMSw4SAcsMd26SecRwRtStFrwdBkwdPos
      parameter data prototype Val: sw-calibration-access=READ-WRITE, type=UInt16
    KeSMSw4SAcsMd26SecRwRtStFrwdBkwdPosMax
      parameter data prototype Val: sw-calibration-access=READ-WRITE, type=UInt16
    KeSMSw4SAcsMd26SecRwRtStFrwdBkwdPosMin
      parameter data prototype Val: sw-calibration-access=READ-WRITE, type=UInt16
    Pos
      parameter data prototype Val: sw-calibration-access=READ-WRITE, type=UInt16
package /PATAC/MSM/ModeAdjust/DataType
  impl type TrgtPosCalibArray: category=ARRAY, sw-calibration-access=READ-ONLY, type-emitter=RTE  # 0:pos 1:max 2:min
    element Element: array-size=3, array-size-semantics=FIXED-SIZE, implementation-data-type=UInt16, invalid-value=0
package /PATAC/MSM/ModeAdjust/Interfaces
  sender receiver interface IfVeSMSuSecRwLtStFrwdBkwdPosV: invalidation-policy{data-element=IfVeSMSuSecRwLtStFrwdBkwdPosV/Val, handle-invalid=DONT-INVALIDATE}
    data Val: type=Boolean
package /PATAC/MSM/ModeAdjust/PortInterface
  client server interface SecRwRtStFwdBkwdTrgtPosSelc
    operation Cal
  client server interface VIPR557TrgtPos
    operation Get
      5 x arg, all with type=UInt16, direction=OUT, server-argument-impl-policy=USE-ARGUMENT-TYPE:
        SecRwLtStBkReclnTrgtPos
        SecRwLtStZeroTrgtPos
        SecRwLtStLgrstUpwdDnwdTrgtPos
        SecRwLtStLgrstInwdOtwdTrgtPos
        SecRwLtStFwdBkwdTrgtPos
    operation Set
      5 x arg, all with type=UInt16, direction=IN, server-argument-impl-policy=USE-ARGUMENT-TYPE:
        SecRwLtStBkReclnTrgtPos
        SecRwLtStZeroTrgtPos
        SecRwLtStLgrstUpwdDnwdTrgtPos
        SecRwLtStLgrstInwdOtwdTrgtPos
        SecRwLtStFwdBkwdTrgtPos
  client server interface VIPRExit557TrgtPos
    operation Get
      11 x arg, all with type=UInt16, direction=OUT, server-argument-impl-policy=USE-ARGUMENT-TYPE:
        SecRwRtStBkReclnTrgtPos
        SecRwRtStZeroTrgtPos
        SecRwRtStLgrstUpwdDnwdTrgtPos
        SecRwRtStLgrstInwdOtwdTrgtPos
        ThdRwLtStBkReclnTrgtPos
        ThdRwLtStFwdBkwdTrgtPos
        ThdRwRtStBkReclnTrgtPos
        ThdRwRtStFwdBkwdTrgtPos
        PassStBkReclnTrgtPos
        PassStFwdBkwdTrgtPos
        SecRwRtStFwdBkwdTrgtPos
    operation Set
  sender receiver interface StNumFlg
    4 x data, all with type=Boolean:
      Is4s
      Is6s
      Is6s7s
      Is7s
    invalidation-policys:
      data-element=Is4s, handle-invalid=DONT-INVALIDATE
      data-element=Is6s, handle-invalid=DONT-INVALIDATE
      data-element=Is6s7s, handle-invalid=DONT-INVALIDATE
      data-element=Is7s, handle-invalid=DONT-INVALIDATE
  sender receiver interface TrgtPosCalibArray: invalidation-policy{data-element=TrgtPosArray, handle-invalid=DONT-INVALIDATE}
    data TrgtPosArray: type=TrgtPosCalibArray  # 0:Pos 1:Max 2:Min
package /PATAC/MSM/PortInterfaces
  sender receiver interface IfVeSMSbSecRwRtStCshnFrntUpwdDnwdMovConfig: invalidation-policy{data-element=IfVeSMSbSecRwRtStCshnFrntUpwdDnwdMovConfig/Val, handle-invalid=DONT-INVALIDATE}
    data Val: type=Boolean
  sender receiver interface IfVeSMSuSecRwLtStFrwdBkwdPos: invalidation-policy{data-element=IfVeSMSuSecRwLtStFrwdBkwdPos/Val, handle-invalid=DONT-INVALIDATE}
    data Val: type=UInt16
